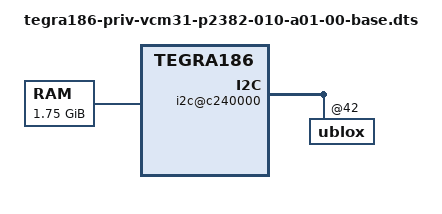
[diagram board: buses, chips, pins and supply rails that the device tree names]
/*
 * tegra186-priv-vcm31-p2382-010-a01-00-base.dts: P2382(sunstreaker) base dts
 * file
 *
 * Copyright (c) 2015 - 2016, NVIDIA CORPORATION.  All rights reserved.
 *
 * This program is free software; you can redistribute it and/or modify
 * it under the terms of the GNU General Public License as published by
 * the Free Software Foundation; version 2 of the License.
 *
 * This program is distributed in the hope that it will be useful, but WITHOUT
 * ANY WARRANTY; without even the implied warranty of MERCHANTABILITY or
 * FITNESS FOR A PARTICULAR PURPOSE.  See the GNU General Public License for
 * more details.
 */

#include "tegra186-platforms/tegra186-vcm31-p2382-common.dtsi"
#include "tegra186-platforms/tegra186-vcm31-p2382-disp.dtsi"
#include "tegra186-prod/tegra186-priv-vcm31-p2382-010-a01-00-prod.dtsi"

/ {
	nvidia,dtsfilename = __FILE__;
	nvidia,boardids = "p2382:0010:A01";
	nvidia,proc-boardid = "p2382:0010:A01";

	memory@80000000 {
		device_type = "memory";
		reg = <0x0 0x80000000 0x0 0x70000000>;
	};

	firmware {
		android {
			compatible = "android,firmware";
			hardware = "p2382_t186";
		};
	};

#ifndef CONFIG_ANDROID
	i2c@c240000 {
		ublox@42 {
			status = "okay";
		};
	};
#endif

#ifdef CONFIG_ANDROID
	/* TBD : once runtime PM is implemented in rtcpu driver, it will be removed
	Bug 200205818, 200191464, 1614189
	*/
	rtcpu@b000000 { /* don't use SCE as camera-rtcpu */
		status = "disabled";
	};
#endif
};
